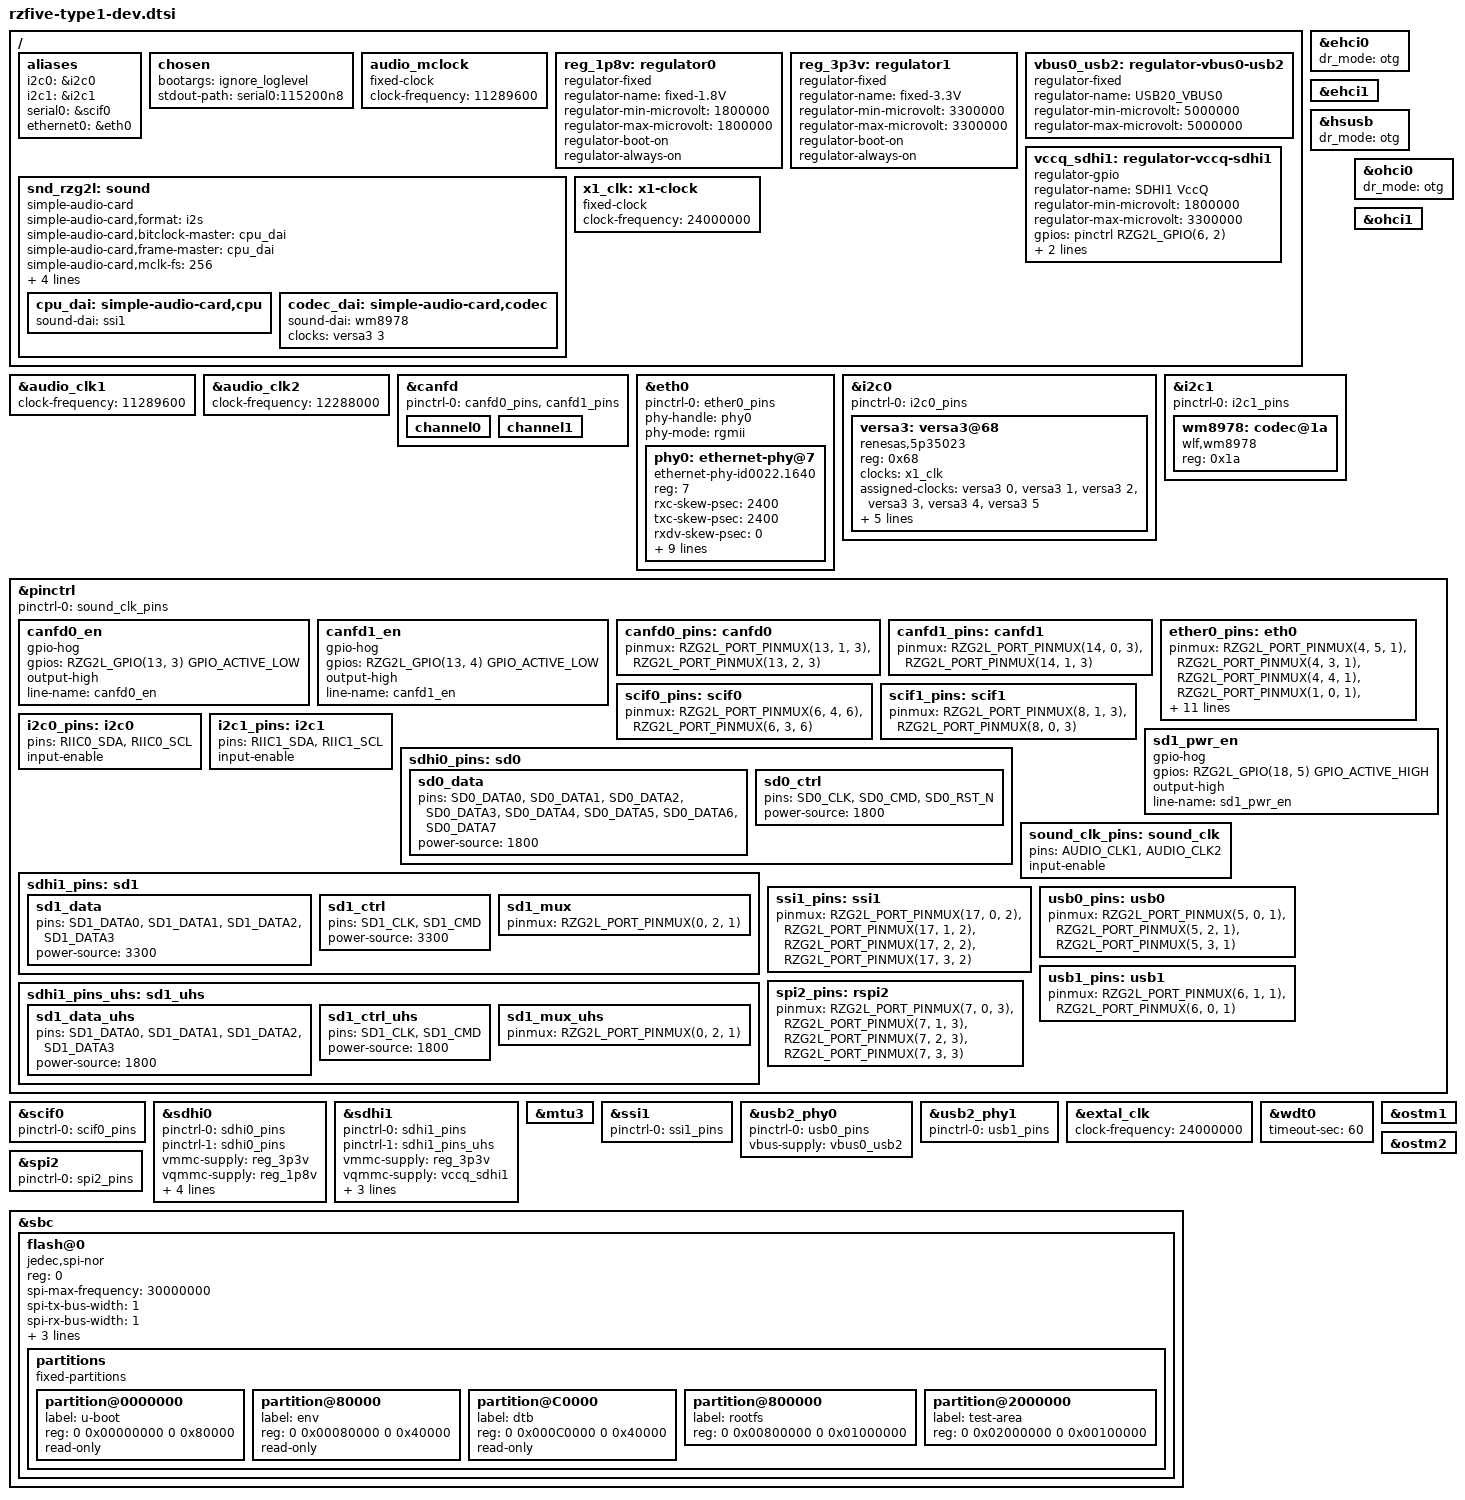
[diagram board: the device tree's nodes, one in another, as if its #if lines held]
// SPDX-License-Identifier: GPL-2.0
/*
 * Device Tree Source for the RZ/Five Type1 dev board common parts
 *
 * Copyright (C) 2022 Renesas Electronics Corp.
 */

#include <dt-bindings/pinctrl/rzg2l-pinctrl.h>
#include <dt-bindings/gpio/gpio.h>

/*
 * Jumper setting
 *
 * Please change the jumper setting coresponding to below Macros:
 *
 * JP1:  1: JP1-1  SD1_WP
*/
#define	JP1	0

#define	SDHI0_SDSLOT		0

#define	CN4_PMOD		0
#define	CN4_CAN_AUDIO		1

#define	CN11_PMOD		0
#define	CN11_ETHER0		1

#define	CN12_PMOD		1
#define	CN12_ETHER1		0

#if (CN4_PMOD & CN4_CAN_AUDIO)
#error "RZ/Five can not enable CN4_PMOD and CN4_CAN_AUDIO simultaneously"
#endif
#if (CN11_PMOD & CN11_ETHER0)
#error "RZ/Five can not enable CN11_PMOD and CN11_ETHER0 simultaneously"
#endif
#if (CN12_PMOD & CN12_ETHER1)
#error "RZ/Five can not enable CN12_PMOD and CN12_ETHER1 simultaneously"
#endif

/ {
	aliases {
		i2c0 = &i2c0;
		i2c1 = &i2c1;
		serial0 = &scif0;
#if (CN11_ETHER0)
		ethernet0 = &eth0;
#endif
#if (CN12_ETHER1)
		ethernet1 = &eth1;
#endif
	};

	chosen {
		bootargs = "ignore_loglevel";
		stdout-path = "serial0:115200n8";
	};

	audio_mclock: audio_mclock {
		compatible = "fixed-clock";
		#clock-cells = <0>;
		clock-frequency = <11289600>;
	};

	reg_1p8v: regulator0 {
		compatible = "regulator-fixed";

		regulator-name = "fixed-1.8V";
		regulator-min-microvolt = <1800000>;
		regulator-max-microvolt = <1800000>;
		regulator-boot-on;
		regulator-always-on;
	};

	reg_3p3v: regulator1 {
		compatible = "regulator-fixed";

		regulator-name = "fixed-3.3V";
		regulator-min-microvolt = <3300000>;
		regulator-max-microvolt = <3300000>;
		regulator-boot-on;
		regulator-always-on;
	};

	vbus0_usb2: regulator-vbus0-usb2 {
		compatible = "regulator-fixed";

		regulator-name = "USB20_VBUS0";
		regulator-min-microvolt = <5000000>;
		regulator-max-microvolt = <5000000>;
	};

#if (CN4_CAN_AUDIO)
	snd_rzg2l: sound {
		compatible = "simple-audio-card";
		simple-audio-card,format = "i2s";
		simple-audio-card,bitclock-master = <&cpu_dai>;
		simple-audio-card,frame-master = <&cpu_dai>;
		simple-audio-card,mclk-fs = <256>;

		simple-audio-card,widgets = "Microphone", "Microphone Jack";
		simple-audio-card,routing =
			    "L2", "Mic Bias",
			    "R2", "Mic Bias",
			    "Mic Bias", "Microphone Jack";

		cpu_dai: simple-audio-card,cpu {
			sound-dai = <&ssi1>;
		};

		codec_dai: simple-audio-card,codec {
			sound-dai = <&wm8978>;
			clocks = <&versa3 3>;
		};
	};
#endif

#if SDHI0_SDSLOT
	vccq_sdhi0: regulator-vccq-sdhi0 {
		compatible = "regulator-gpio";

		regulator-name = "SDHI0 VccQ";
		regulator-min-microvolt = <1800000>;
		regulator-max-microvolt = <3300000>;

		gpios = <&pinctrl RZG2L_GPIO(5, 4) GPIO_ACTIVE_HIGH>;

		gpios-states = <1>;
		states = <3300000 1
			  1800000 0>;
	};
#endif

	vccq_sdhi1: regulator-vccq-sdhi1 {
		compatible = "regulator-gpio";

		regulator-name = "SDHI1 VccQ";
		regulator-min-microvolt = <1800000>;
		regulator-max-microvolt = <3300000>;

		gpios = <&pinctrl RZG2L_GPIO(6, 2) GPIO_ACTIVE_HIGH>;

		gpios-states = <1>;
		states = <3300000 1
			  1800000 0>;
	};

	x1_clk: x1-clock {
		compatible = "fixed-clock";
		#clock-cells = <0>;
		clock-frequency = <24000000>;
	};
};

&audio_clk1{
	clock-frequency = <11289600>;
};

&audio_clk2{
	clock-frequency = <12288000>;
};

#if (CN4_CAN_AUDIO)
&canfd {
	pinctrl-0 = <&canfd0_pins &canfd1_pins>;
	pinctrl-names = "default";
	status = "okay";
	channel0 {
		status = "okay";
	};
	channel1 {
		status = "okay";
	};
};
#endif

&ehci0 {
	dr_mode = "otg";
	status = "okay";
};

&ehci1 {
	status = "okay";
};

#if (CN11_ETHER0)
&eth0 {
	pinctrl-0 = <&ether0_pins>;
	pinctrl-names = "default";
	phy-handle = <&phy0>;
	phy-mode = "rgmii";
	status = "okay";

	phy0: ethernet-phy@7 {
		compatible = "ethernet-phy-id0022.1640",
				 "ethernet-phy-ieee802.3-c22";
		reg = <7>;
		rxc-skew-psec = <2400>;
		txc-skew-psec = <2400>;
		rxdv-skew-psec = <0>;
		txdv-skew-psec = <0>;
		rxd0-skew-psec = <0>;
		rxd1-skew-psec = <0>;
		rxd2-skew-psec = <0>;
		rxd3-skew-psec = <0>;
		txd0-skew-psec = <0>;
		txd1-skew-psec = <0>;
		txd2-skew-psec = <0>;
		txd3-skew-psec = <0>;
	};
};
#endif

#if (CN12_ETHER1)
&eth1 {
	pinctrl-0 = <&ether1_pins>;
	pinctrl-names = "default";
	phy-handle = <&phy1>;
	phy-mode = "rgmii";
	status = "okay";

	phy1: ethernet-phy@7 {
		compatible = "ethernet-phy-id0022.1640",
			     "ethernet-phy-ieee802.3-c22";
		reg = <7>;
		rxc-skew-psec = <2400>;
		txc-skew-psec = <2400>;
		rxdv-skew-psec = <0>;
		txdv-skew-psec = <0>;
		rxd0-skew-psec = <0>;
		rxd1-skew-psec = <0>;
		rxd2-skew-psec = <0>;
		rxd3-skew-psec = <0>;
		txd0-skew-psec = <0>;
		txd1-skew-psec = <0>;
		txd2-skew-psec = <0>;
		txd3-skew-psec = <0>;
		// interrupt-parent = <&pinctrl>;
		// interrupts = <RZG2L_GPIO(14, 2) IRQ_TYPE_EDGE_FALLING>;
	};
};
#endif

&hsusb {
	dr_mode = "otg";
	status = "okay";
};

&i2c0 {
	pinctrl-0 = <&i2c0_pins>;
	pinctrl-names = "default";

	status = "okay";

	versa3: versa3@68 {
		compatible = "renesas,5p35023";
		reg = <0x68>;
		#clock-cells = <1>;
		clocks = <&x1_clk>;
		clock-names = "x1";
		assigned-clocks = <&versa3 0>,
				   <&versa3 1>,
				   <&versa3 2>,
				   <&versa3 3>,
				   <&versa3 4>,
				   <&versa3 5>;
		assigned-clock-rates =	<12288000>, <25000000>,
					<12000000>, <11289600>,
					<11289600>, <24000000>;
		clock-divider-read-only = <1>, <1>, <1>, <1>, <1>;
		clock-flags = <2176>, <2176>, <2176>, <2052>, <2176>, <2048>;
	};
};

&i2c1 {
	pinctrl-0 = <&i2c1_pins>;
	pinctrl-names = "default";
	status = "okay";

#if (CN4_CAN_AUDIO)
	wm8978: codec@1a {
		compatible = "wlf,wm8978";
		#sound-dai-cells = <0>;
		reg = <0x1a>;
	};
#endif
};

&ohci0 {
	dr_mode = "otg";
	status = "okay";
};

&ohci1 {
	status = "okay";
};

&pinctrl {
	pinctrl-0 = <&sound_clk_pins>;
	pinctrl-names = "default";

#if (CN4_CAN_AUDIO)
	canfd0_en {
		gpio-hog;
		gpios = <RZG2L_GPIO(13, 3) GPIO_ACTIVE_LOW>;
		output-high;
		line-name = "canfd0_en";
	};

	canfd1_en {
		gpio-hog;
		gpios = <RZG2L_GPIO(13, 4) GPIO_ACTIVE_LOW>;
		output-high;
		line-name = "canfd1_en";
	};

	canfd0_pins: canfd0 {
		pinmux = <RZG2L_PORT_PINMUX(13, 1, 3)>, /* TX */
			 <RZG2L_PORT_PINMUX(13, 2, 3)>; /* RX */
	};

	canfd1_pins: canfd1 {
		pinmux = <RZG2L_PORT_PINMUX(14, 0, 3)>, /* TX */
			 <RZG2L_PORT_PINMUX(14, 1, 3)>; /* RX */
	};
#endif

#if (CN11_ETHER0)
	ether0_pins: eth0 {
		pinmux = <RZG2L_PORT_PINMUX(4, 5, 1)>, /* ET0_LINKSTA */
			 <RZG2L_PORT_PINMUX(4, 3, 1)>, /* ET0_MDC */
			 <RZG2L_PORT_PINMUX(4, 4, 1)>, /* ET0_MDIO */
			 <RZG2L_PORT_PINMUX(1, 0, 1)>, /* ET0_TXC */
			 <RZG2L_PORT_PINMUX(1, 1, 1)>, /* ET0_TX_CTL */
			 <RZG2L_PORT_PINMUX(1, 2, 1)>, /* ET0_TXD0 */
			 <RZG2L_PORT_PINMUX(1, 3, 1)>, /* ET0_TXD1 */
			 <RZG2L_PORT_PINMUX(1, 4, 1)>, /* ET0_TXD2 */
			 <RZG2L_PORT_PINMUX(2, 0, 1)>, /* ET0_TXD3 */
			 <RZG2L_PORT_PINMUX(3, 0, 1)>, /* ET0_RXC */
			 <RZG2L_PORT_PINMUX(3, 1, 1)>, /* ET0_RX_CTL */
			 <RZG2L_PORT_PINMUX(3, 2, 1)>, /* ET0_RXD0 */
			 <RZG2L_PORT_PINMUX(3, 3, 1)>, /* ET0_RXD1 */
			 <RZG2L_PORT_PINMUX(4, 0, 1)>, /* ET0_RXD2 */
			 <RZG2L_PORT_PINMUX(4, 1, 1)>; /* ET0_RXD3 */
	};
#endif

#if (CN12_ETHER1)
	ether1_pins: eth1 {
		pinmux = <RZG2L_PORT_PINMUX(10, 4, 1)>, /* ET1_LINKSTA */
			 <RZG2L_PORT_PINMUX(10, 2, 1)>, /* ET1_MDC */
			 <RZG2L_PORT_PINMUX(10, 3, 1)>, /* ET1_MDIO */
			 <RZG2L_PORT_PINMUX(7, 0, 1)>, /* ET1_TXC */
			 <RZG2L_PORT_PINMUX(7, 1, 1)>, /* ET1_TX_CTL */
			 <RZG2L_PORT_PINMUX(7, 2, 1)>, /* ET1_TXD0 */
			 <RZG2L_PORT_PINMUX(7, 3, 1)>, /* ET1_TXD1 */
			 <RZG2L_PORT_PINMUX(7, 4, 1)>, /* ET1_TXD2 */
			 <RZG2L_PORT_PINMUX(8, 0, 1)>, /* ET1_TXD3 */
			 <RZG2L_PORT_PINMUX(8, 4, 1)>, /* ET1_RXC */
			 <RZG2L_PORT_PINMUX(9, 0, 1)>, /* ET1_RX_CTL */
			 <RZG2L_PORT_PINMUX(9, 1, 1)>, /* ET1_RXD0 */
			 <RZG2L_PORT_PINMUX(9, 2, 1)>, /* ET1_RXD1 */
			 <RZG2L_PORT_PINMUX(9, 3, 1)>, /* ET1_RXD2 */
			 <RZG2L_PORT_PINMUX(10, 0, 1)>; /* ET1_RXD3 */
	};
#endif

	scif0_pins: scif0 {
		pinmux = <RZG2L_PORT_PINMUX(6, 4, 6)>, /* TX */
			 <RZG2L_PORT_PINMUX(6, 3, 6)>; /* RX */
	};

#if (CN12_PMOD)
	scif1_pins: scif1 {
		pinmux = <RZG2L_PORT_PINMUX(8, 1, 3)>, /* TX */
			 <RZG2L_PORT_PINMUX(8, 0, 3)>; /* RX */
	};
#endif

	i2c0_pins: i2c0 {
		pins = "RIIC0_SDA", "RIIC0_SCL";
		input-enable;
	};

	i2c1_pins: i2c1 {
		pins = "RIIC1_SDA", "RIIC1_SCL";
		input-enable;
	};

#if (SDHI0_SDSLOT)
	sd0_pwr_en {
		gpio-hog;
		gpios = <RZG2L_GPIO(18, 4) GPIO_ACTIVE_HIGH>;
		output-high;
		line-name = "sd0_pwr_en";
	};
#endif

	sd1_pwr_en {
		gpio-hog;
		gpios = <RZG2L_GPIO(18, 5) GPIO_ACTIVE_HIGH>;
		output-high;
		line-name = "sd1_pwr_en";
	};

#if !(SDHI0_SDSLOT)
	/* Support pinctrl for MMC function of SDHI0*/
	sdhi0_pins: sd0 {
		sd0_data {
			pins =  "SD0_DATA0", "SD0_DATA1", "SD0_DATA2",
				"SD0_DATA3", "SD0_DATA4", "SD0_DATA5",
				"SD0_DATA6", "SD0_DATA7";
			power-source  = <1800>;
		};

		sd0_ctrl {
			pins = "SD0_CLK", "SD0_CMD", "SD0_RST_N";
			power-source = <1800>;
		};
	};
#else
	/* Support pinctrl for SD function of SDHI0 */
	sdhi0_pins: sd0 {
		sd0_data {
			pins =  "SD0_DATA0", "SD0_DATA1", "SD0_DATA2",
				"SD0_DATA3";
			power-source  = <3300>;
		};

		sd0_ctrl {
			pins = "SD0_CLK", "SD0_CMD";
			power-source = <3300>;
		};

		sd0_mux {
			pinmux = <RZG2L_PORT_PINMUX(0, 0, 1)>, /* CD */
				 <RZG2L_PORT_PINMUX(0, 1, 1)>; /* WP */
		};
	};

	sdhi0_pins_uhs: sd0_uhs {
		sd0_data_uhs {
			pins =	"SD0_DATA0", "SD0_DATA1", "SD0_DATA2",
				"SD0_DATA3";
			power-source  = <1800>;
		};

		sd0_ctrl_uhs {
			pins = "SD0_CLK", "SD0_CMD";
			power-source  = <1800>;
		};

		sd0_mux_uhs {
			pinmux = <RZG2L_PORT_PINMUX(0, 0, 1)>, /* CD */
				 <RZG2L_PORT_PINMUX(0, 1, 1)>; /* WP */
		};
	};
#endif

	sdhi1_pins: sd1 {
		sd1_data {
			pins =	"SD1_DATA0", "SD1_DATA1", "SD1_DATA2",
				"SD1_DATA3";
			power-source  = <3300>;
		};

		sd1_ctrl {
			pins = "SD1_CLK", "SD1_CMD";
			power-source  = <3300>;
		};

		sd1_mux {
#if (JP1)
			pinmux = <RZG2L_PORT_PINMUX(0, 2, 1)>, /* CD */
				 <RZG2L_PORT_PINMUX(0, 3, 1)>; /* WP */
#else
			pinmux = <RZG2L_PORT_PINMUX(0, 2, 1)>; /* CD */
#endif
		};
	};

	sdhi1_pins_uhs: sd1_uhs {
		sd1_data_uhs {
			pins =	"SD1_DATA0", "SD1_DATA1", "SD1_DATA2",
				"SD1_DATA3";
			power-source  = <1800>;
		};

		sd1_ctrl_uhs {
			pins = "SD1_CLK", "SD1_CMD";
			power-source  = <1800>;
		};

		sd1_mux_uhs {
#if (JP1)
			pinmux = <RZG2L_PORT_PINMUX(0, 2, 1)>, /* CD */
				 <RZG2L_PORT_PINMUX(0, 3, 1)>; /* WP */
#else
			pinmux = <RZG2L_PORT_PINMUX(0, 2, 1)>; /* CD */
#endif
		};
	};

	sound_clk_pins: sound_clk {
		pins = "AUDIO_CLK1", "AUDIO_CLK2";
		input-enable;
	};

#if (CN4_CAN_AUDIO)
	ssi1_pins: ssi1 {
		pinmux = <RZG2L_PORT_PINMUX(17, 0, 2)>, /* BCK */
			 <RZG2L_PORT_PINMUX(17, 1, 2)>, /* RCK */
			 <RZG2L_PORT_PINMUX(17, 2, 2)>, /* TXD */
			 <RZG2L_PORT_PINMUX(17, 3, 2)>; /* RXD */
	};
#endif

	usb0_pins: usb0 {
		pinmux = <RZG2L_PORT_PINMUX(5, 0, 1)>, /* VBUS */
			 <RZG2L_PORT_PINMUX(5, 2, 1)>, /* OVC */
			 <RZG2L_PORT_PINMUX(5, 3, 1)>; /* OTG_ID */
	};

	usb1_pins: usb1 {
		pinmux = <RZG2L_PORT_PINMUX(6, 1, 1)>, /* OVC */
			 <RZG2L_PORT_PINMUX(6, 0, 1)>; /* VBUS */
	};

#if (CN4_PMOD)
	spi1_pins: rspi1 {
		pinmux = <RZG2L_PORT_PINMUX(17, 0, 1)>, /* CK */
			 <RZG2L_PORT_PINMUX(17, 1, 1)>, /* MOSI */
			 <RZG2L_PORT_PINMUX(17, 2, 1)>, /* MISO */
			 <RZG2L_PORT_PINMUX(17, 3, 1)>; /* SSL */
	};
#endif

#if (CN11_PMOD)
	spi0_pins: rspi0 {
		pinmux = <RZG2L_PORT_PINMUX(1, 0, 2)>, /* CK */
			 <RZG2L_PORT_PINMUX(1, 1, 2)>, /* MOSI */
			 <RZG2L_PORT_PINMUX(1, 2, 2)>, /* MISO */
			 <RZG2L_PORT_PINMUX(1, 3, 2)>; /* SSL */
	};

	spi1_pins: rspi1 {
		pinmux = <RZG2L_PORT_PINMUX(4, 0, 2)>, /* CK */
			 <RZG2L_PORT_PINMUX(4, 1, 2)>, /* MOSI */
			 <RZG2L_PORT_PINMUX(4, 2, 2)>, /* MISO */
			 <RZG2L_PORT_PINMUX(4, 3, 2)>; /* SSL */
	};
#endif

#if (CN12_PMOD)
	spi2_pins: rspi2 {
		pinmux = <RZG2L_PORT_PINMUX(7, 0, 3)>, /* CK */
			 <RZG2L_PORT_PINMUX(7, 1, 3)>, /* MOSI */
			 <RZG2L_PORT_PINMUX(7, 2, 3)>, /* MISO */
			 <RZG2L_PORT_PINMUX(7, 3, 3)>; /* SSL */
	};
#endif
};

&scif0 {
	pinctrl-0 = <&scif0_pins>;
	pinctrl-names = "default";
	status = "okay";
};

#if !(SDHI0_SDSLOT)
&sdhi0 {
	pinctrl-0 = <&sdhi0_pins>;
	pinctrl-1 = <&sdhi0_pins>;
	pinctrl-names = "default", "state_uhs";

	vmmc-supply = <&reg_3p3v>;
	vqmmc-supply = <&reg_1p8v>;
	bus-width = <8>;
	mmc-hs200-1_8v;
	non-removable;
	fixed-emmc-driver-type = <1>;
	status = "okay";
};
#else
&sdhi0 {
	pinctrl-0 = <&sdhi0_pins>;
	pinctrl-1 = <&sdhi0_pins_uhs>;
	pinctrl-names = "default", "state_uhs";

	vmmc-supply = <&reg_3p3v>;
	vqmmc-supply = <&vccq_sdhi0>;

	bus-width = <4>;
	sd-uhs-sdr50;
	sd-uhs-sdr104;
	status = "okay";
};
#endif

&sdhi1 {
	pinctrl-0 = <&sdhi1_pins>;
	pinctrl-1 = <&sdhi1_pins_uhs>;
	pinctrl-names = "default", "state_uhs";

	vmmc-supply = <&reg_3p3v>;
	vqmmc-supply = <&vccq_sdhi1>;

	bus-width = <4>;
	sd-uhs-sdr50;
	sd-uhs-sdr104;
	status = "okay";
};

&mtu3 {
	status = "okay";
};

#if (CN4_CAN_AUDIO)
&ssi1 {
	pinctrl-0 = <&ssi1_pins>;
	pinctrl-names = "default";

	status = "okay";
};
#endif

&usb2_phy0 {
	pinctrl-0 = <&usb0_pins>;
	pinctrl-names = "default";

	vbus-supply = <&vbus0_usb2>;
	status = "okay";
};

&usb2_phy1 {
	pinctrl-0 = <&usb1_pins>;
	pinctrl-names = "default";

	status = "okay";
};

&extal_clk {
	clock-frequency = <24000000>;
};

&wdt0 {
	status = "okay";
	timeout-sec = <60>;
};

#if (CN4_PMOD)
&rspi1 {
	pinctrl-0 = <&spi1_pins>;
	pinctrl-names = "default";
	status = "okay";
};
#endif

#if (CN11_PMOD)
&spi0 {
	pinctrl-0 = <&spi0_pins>;
	pinctrl-names = "default";
	status = "okay";
};

&spi1 {
	pinctrl-0 = <&spi1_pins>;
	pinctrl-names = "default";
	status = "okay";
};
#endif

#if (CN12_PMOD)
&spi2 {
	pinctrl-0 = <&spi2_pins>;
	pinctrl-names = "default";
	status = "okay";
};
#endif

&sbc {
	status = "okay";

	flash@0 {
		compatible = "jedec,spi-nor";
		reg = <0>;
		spi-max-frequency = <30000000>;

		spi-tx-bus-width = <1>;
		spi-rx-bus-width = <1>;

		/* SPI Mode 3 */
		spi-cpol;
		spi-cpha;
		m25p,fast-read;

		partitions {
			compatible = "fixed-partitions";
			#address-cells = <2>;
			#size-cells = <2>;

			partition@0000000 {
				label = "u-boot";
				reg = <0 0x00000000 0 0x80000>;
				read-only;
			};
			partition@80000 {
				label = "env";
				reg = <0 0x00080000 0 0x40000>;
				read-only;
			};
			partition@C0000 {
				label = "dtb";
				reg = <0 0x000C0000 0 0x40000>;
				read-only;
			};
			partition@800000 {
				label = "rootfs";
				/* 16MB @ 8MB offset in SPI Flash */
				reg = <0 0x00800000 0 0x01000000>;
			};
			partition@2000000 {
				label = "test-area";
				reg = <0 0x02000000 0 0x00100000>;
			};
		};
	};
};

&ostm1 {
	status = "okay";
};

&ostm2 {
	status = "okay";
};
